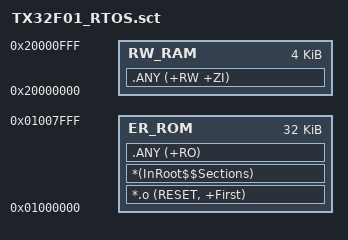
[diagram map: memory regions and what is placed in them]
; APP_RTOS: bare-metal, full 32KB flash, no bootloader
LR_ROM 0x01000000 0x00008000  {
  ER_ROM 0x01000000 0x00008000  {
    *.o (RESET, +First)
    *(InRoot$$Sections)
    .ANY (+RO)
  }
  RW_RAM 0x20000000 0x00001000  {
    .ANY (+RW +ZI)
  }
}
